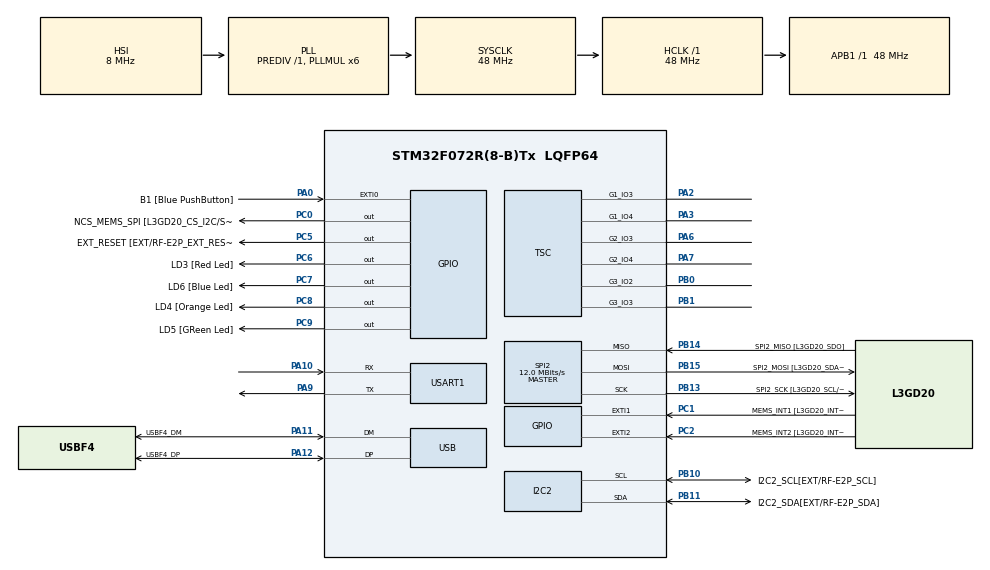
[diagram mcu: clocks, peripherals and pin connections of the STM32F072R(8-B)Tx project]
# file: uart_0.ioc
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I2C2.Timing=0x20303E5D
Mcu.Family=STM32F0
Mcu.Name=STM32F072R(8-B)Tx
Mcu.Package=LQFP64
NVIC.USART1_IRQn=true\:1\:0\:true\:false\:true\:true\:true\:true
PA0.GPIO_Label=B1 [Blue PushButton]
PA0.GPIO_ModeDefaultEXTI=GPIO_MODE_EVT_RISING
PA0.Signal=GPXTI0
PA10.Mode=Asynchronous
PA10.Signal=USART1_RX
PA11.GPIO_Label=USBF4_DM
PA11.Mode=Device
PA11.Signal=USB_DM
PA12.GPIO_Label=USBF4_DP
PA12.Mode=Device
PA12.Signal=USB_DP
PA13.GPIO_Label=SWDIO
PA13.Mode=Serial_Wire
PA13.Signal=SYS_SWDIO
PA14.GPIO_Label=SWCLK
PA14.Mode=Serial_Wire
PA14.Signal=SYS_SWCLK
PA2.Mode=G1_IO3-Channel
PA2.Signal=TSC_G1_IO3
PA3.Mode=G1_IO4-Sampling
PA3.Signal=TSC_G1_IO4
PA6.Mode=G2_IO3-Channel
PA6.Signal=TSC_G2_IO3
PA7.Mode=G2_IO4-Sampling
PA7.Signal=TSC_G2_IO4
PA9.Mode=Asynchronous
PA9.Signal=USART1_TX
PB0.Mode=G3_IO2-Channel
PB0.Signal=TSC_G3_IO2
PB1.Mode=G3_IO3-Sampling
PB1.Signal=TSC_G3_IO3
PB10.GPIO_Label=I2C2_SCL[EXT/RF-E2P_SCL]
PB10.GPIO_Pu=GPIO_PULLUP
PB10.Mode=I2C
PB10.Signal=I2C2_SCL
PB11.GPIO_Label=I2C2_SDA[EXT/RF-E2P_SDA]
PB11.GPIO_Pu=GPIO_PULLUP
PB11.Mode=I2C
PB11.Signal=I2C2_SDA
PB13.GPIO_Label=SPI2_SCK [L3GD20_SCL/SPC]
PB13.Mode=Full_Duplex_Master
PB13.Signal=SPI2_SCK
PB14.GPIO_Label=SPI2_MISO [L3GD20_SDO]
PB14.Mode=Full_Duplex_Master
PB14.Signal=SPI2_MISO
PB15.GPIO_Label=SPI2_MOSI [L3GD20_SDA/SDI]
PB15.Mode=Full_Duplex_Master
PB15.Signal=SPI2_MOSI
PC0.GPIO_Label=NCS_MEMS_SPI [L3GD20_CS_I2C/SPI]
PC0.Signal=GPIO_Output
PC1.GPIO_Label=MEMS_INT1 [L3GD20_INT1]
PC1.GPIO_ModeDefaultEXTI=GPIO_MODE_EVT_RISING
PC1.Signal=GPXTI1
PC2.GPIO_Label=MEMS_INT2 [L3GD20_INT2]
PC2.GPIO_ModeDefaultEXTI=GPIO_MODE_EVT_RISING
PC2.Signal=GPXTI2
PC5.GPIO_Label=EXT_RESET [EXT/RF-E2P_EXT_RESET]
PC5.Signal=GPIO_Output
PC6.GPIO_Label=LD3 [Red Led]
PC6.Signal=GPIO_Output
PC7.GPIO_Label=LD6 [Blue Led]
PC7.Signal=GPIO_Output
PC8.GPIO_Label=LD4 [Orange Led]
PC8.Signal=GPIO_Output
PC9.GPIO_Label=LD5 [GReen Led]
PC9.Signal=GPIO_Output
ProjectManager.HeapSize=0x200
ProjectManager.StackSize=0x400
ProjectManager.TargetToolchain=STM32CubeIDE
RCC.AHBFreq_Value=48000000
RCC.APB1Freq_Value=48000000
RCC.APB1TimFreq_Value=48000000
RCC.HCLKFreq_Value=48000000
RCC.PLLMUL=RCC_PLL_MUL6
RCC.SYSCLKFreq_VALUE=48000000
RCC.SYSCLKSource=RCC_SYSCLKSOURCE_PLLCLK
SPI2.BaudRatePrescaler=SPI_BAUDRATEPRESCALER_4
SPI2.CalculateBaudRate=12.0 MBits/s
SPI2.Direction=SPI_DIRECTION_2LINES
SPI2.Mode=SPI_MODE_MASTER
SPI2.VirtualType=VM_MASTER
USART1.VirtualMode-Asynchronous=VM_ASYNC
USB.phy_itface=PCD_PHY_EMBEDDED
USB.speed=PCD_SPEED_FULL
board=STM32F072B-DISCO

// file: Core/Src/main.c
/* USER CODE BEGIN Header */
/**
  ******************************************************************************
  * @file           : main.c
  * @brief          : Main program body
  ******************************************************************************
  * @attention
  *
  * Copyright (c) 2024 STMicroelectronics.
  * All rights reserved.
  *
  * This software is licensed under terms that can be found in the LICENSE file
  * in the root directory of this software component.
  * If no LICENSE file comes with this software, it is provided AS-IS.
  *
  ******************************************************************************
  */
/* USER CODE END Header */
#include "main.h"
#include <string.h>
/* USER CODE BEGIN Includes */
#include "stdbool.h"
/* USER CODE END Includes */
uint8_t data_rx[1];

I2C_HandleTypeDef hi2c2;

SPI_HandleTypeDef hspi2;

TSC_HandleTypeDef htsc;

UART_HandleTypeDef huart1;

PCD_HandleTypeDef hpcd_USB_FS;

void SystemClock_Config(void);
static void MX_GPIO_Init(void);
static void MX_I2C2_Init(void);
static void MX_SPI2_Init(void);
static void MX_TSC_Init(void);
static void MX_USB_PCD_Init(void);
static void MX_USART1_UART_Init(void);

/* USER CODE BEGIN 0 */

uint8_t uart1MainBuf[64];
uint8_t uart1rxLen;
bool uart1CallbackComplete = false;
void SendPongMessage(void);
/* USER CODE END 0 */

int main(void)
{

  /* MCU Configuration--------------------------------------------------------*/

  /* Reset of all peripherals, Initializes the Flash interface and the Systick. */
  HAL_Init();

  /* Configure the system clock */
  SystemClock_Config();

  /* Initialize all configured peripherals */
  MX_GPIO_Init();
  MX_I2C2_Init();
  MX_SPI2_Init();
  MX_TSC_Init();
  MX_USB_PCD_Init();
  MX_USART1_UART_Init();
  HAL_UART_Receive_IT(&huart1, data_rx, 1);

  /* Infinite loop */
  while (1)
  {
	 // HAL_GPIO_TogglePin(LD6_GPIO_Port, LD6_Pin);
	  // HAL_Delay(250);
	  if (uart1CallbackComplete){
		  uart1CallbackComplete = false;
		  if (uart1MainBuf[uart1rxLen -1] == 103){
			  SendPongMessage();
		  }
	  }
  }
}

void SystemClock_Config(void)
{
  RCC_OscInitTypeDef RCC_OscInitStruct = {0};
  RCC_ClkInitTypeDef RCC_ClkInitStruct = {0};
  RCC_PeriphCLKInitTypeDef PeriphClkInit = {0};

  /** Initializes the RCC Oscillators according to the specified parameters
  * in the RCC_OscInitTypeDef structure.
  */
  RCC_OscInitStruct.OscillatorType = RCC_OSCILLATORTYPE_HSI|RCC_OSCILLATORTYPE_HSI48;
  RCC_OscInitStruct.HSIState = RCC_HSI_ON;
  RCC_OscInitStruct.HSI48State = RCC_HSI48_ON;
  RCC_OscInitStruct.HSICalibrationValue = RCC_HSICALIBRATION_DEFAULT;
  RCC_OscInitStruct.PLL.PLLState = RCC_PLL_ON;
  RCC_OscInitStruct.PLL.PLLSource = RCC_PLLSOURCE_HSI;
  RCC_OscInitStruct.PLL.PLLMUL = RCC_PLL_MUL6;
  RCC_OscInitStruct.PLL.PREDIV = RCC_PREDIV_DIV1;
  if (HAL_RCC_OscConfig(&RCC_OscInitStruct) != HAL_OK)
  {
    Error_Handler();
  }

  /** Initializes the CPU, AHB and APB buses clocks
  */
  RCC_ClkInitStruct.ClockType = RCC_CLOCKTYPE_HCLK|RCC_CLOCKTYPE_SYSCLK
                              |RCC_CLOCKTYPE_PCLK1;
  RCC_ClkInitStruct.SYSCLKSource = RCC_SYSCLKSOURCE_PLLCLK;
  RCC_ClkInitStruct.AHBCLKDivider = RCC_SYSCLK_DIV1;
  RCC_ClkInitStruct.APB1CLKDivider = RCC_HCLK_DIV1;

  if (HAL_RCC_ClockConfig(&RCC_ClkInitStruct, FLASH_LATENCY_1) != HAL_OK)
  {
    Error_Handler();
  }
  PeriphClkInit.PeriphClockSelection = RCC_PERIPHCLK_USB|RCC_PERIPHCLK_USART1;
  PeriphClkInit.Usart1ClockSelection = RCC_USART1CLKSOURCE_PCLK1;
  PeriphClkInit.UsbClockSelection = RCC_USBCLKSOURCE_HSI48;

  if (HAL_RCCEx_PeriphCLKConfig(&PeriphClkInit) != HAL_OK)
  {
    Error_Handler();
  }
}

static void MX_I2C2_Init(void)
{

  hi2c2.Instance = I2C2;
  hi2c2.Init.Timing = 0x20303E5D;
  hi2c2.Init.OwnAddress1 = 0;
  hi2c2.Init.AddressingMode = I2C_ADDRESSINGMODE_7BIT;
  hi2c2.Init.DualAddressMode = I2C_DUALADDRESS_DISABLE;
  hi2c2.Init.OwnAddress2 = 0;
  hi2c2.Init.OwnAddress2Masks = I2C_OA2_NOMASK;
  hi2c2.Init.GeneralCallMode = I2C_GENERALCALL_DISABLE;
  hi2c2.Init.NoStretchMode = I2C_NOSTRETCH_DISABLE;
  if (HAL_I2C_Init(&hi2c2) != HAL_OK)
  {
    Error_Handler();
  }

  /** Configure Analogue filter
  */
  if (HAL_I2CEx_ConfigAnalogFilter(&hi2c2, I2C_ANALOGFILTER_ENABLE) != HAL_OK)
  {
    Error_Handler();
  }

  /** Configure Digital filter
  */
  if (HAL_I2CEx_ConfigDigitalFilter(&hi2c2, 0) != HAL_OK)
  {
    Error_Handler();
  }

}

static void MX_SPI2_Init(void)
{

  /* SPI2 parameter configuration*/
  hspi2.Instance = SPI2;
  hspi2.Init.Mode = SPI_MODE_MASTER;
  hspi2.Init.Direction = SPI_DIRECTION_2LINES;
  hspi2.Init.DataSize = SPI_DATASIZE_4BIT;
  hspi2.Init.CLKPolarity = SPI_POLARITY_LOW;
  hspi2.Init.CLKPhase = SPI_PHASE_1EDGE;
  hspi2.Init.NSS = SPI_NSS_SOFT;
  hspi2.Init.BaudRatePrescaler = SPI_BAUDRATEPRESCALER_4;
  hspi2.Init.FirstBit = SPI_FIRSTBIT_MSB;
  hspi2.Init.TIMode = SPI_TIMODE_DISABLE;
  hspi2.Init.CRCCalculation = SPI_CRCCALCULATION_DISABLE;
  hspi2.Init.CRCPolynomial = 7;
  hspi2.Init.CRCLength = SPI_CRC_LENGTH_DATASIZE;
  hspi2.Init.NSSPMode = SPI_NSS_PULSE_ENABLE;
  if (HAL_SPI_Init(&hspi2) != HAL_OK)
  {
    Error_Handler();
  }

}

static void MX_TSC_Init(void)
{

  /** Configure the TSC peripheral
  */
  htsc.Instance = TSC;
  htsc.Init.CTPulseHighLength = TSC_CTPH_2CYCLES;
  htsc.Init.CTPulseLowLength = TSC_CTPL_2CYCLES;
  htsc.Init.SpreadSpectrum = DISABLE;
  htsc.Init.SpreadSpectrumDeviation = 1;
  htsc.Init.SpreadSpectrumPrescaler = TSC_SS_PRESC_DIV1;
  htsc.Init.PulseGeneratorPrescaler = TSC_PG_PRESC_DIV4;
  htsc.Init.MaxCountValue = TSC_MCV_8191;
  htsc.Init.IODefaultMode = TSC_IODEF_OUT_PP_LOW;
  htsc.Init.SynchroPinPolarity = TSC_SYNC_POLARITY_FALLING;
  htsc.Init.AcquisitionMode = TSC_ACQ_MODE_NORMAL;
  htsc.Init.MaxCountInterrupt = DISABLE;
  htsc.Init.ChannelIOs = TSC_GROUP1_IO3|TSC_GROUP2_IO3|TSC_GROUP3_IO2;
  htsc.Init.ShieldIOs = 0;
  htsc.Init.SamplingIOs = TSC_GROUP1_IO4|TSC_GROUP2_IO4|TSC_GROUP3_IO3;
  if (HAL_TSC_Init(&htsc) != HAL_OK)
  {
    Error_Handler();
  }

}

static void MX_USART1_UART_Init(void)
{

  huart1.Instance = USART1;
  huart1.Init.BaudRate = 38400;
  huart1.Init.WordLength = UART_WORDLENGTH_8B;
  huart1.Init.StopBits = UART_STOPBITS_1;
  huart1.Init.Parity = UART_PARITY_NONE;
  huart1.Init.Mode = UART_MODE_TX_RX;
  huart1.Init.HwFlowCtl = UART_HWCONTROL_NONE;
  huart1.Init.OverSampling = UART_OVERSAMPLING_16;
  huart1.Init.OneBitSampling = UART_ONE_BIT_SAMPLE_DISABLE;
  huart1.AdvancedInit.AdvFeatureInit = UART_ADVFEATURE_NO_INIT;
  if (HAL_UART_Init(&huart1) != HAL_OK)
  {
    Error_Handler();
  }

}

static void MX_USB_PCD_Init(void)
{

  hpcd_USB_FS.Instance = USB;
  hpcd_USB_FS.Init.dev_endpoints = 8;
  hpcd_USB_FS.Init.speed = PCD_SPEED_FULL;
  hpcd_USB_FS.Init.phy_itface = PCD_PHY_EMBEDDED;
  hpcd_USB_FS.Init.low_power_enable = DISABLE;
  hpcd_USB_FS.Init.lpm_enable = DISABLE;
  hpcd_USB_FS.Init.battery_charging_enable = DISABLE;
  if (HAL_PCD_Init(&hpcd_USB_FS) != HAL_OK)
  {
    Error_Handler();
  }

}

static void MX_GPIO_Init(void)
{
  GPIO_InitTypeDef GPIO_InitStruct = {0};

  /* GPIO Ports Clock Enable */
  __HAL_RCC_GPIOC_CLK_ENABLE();
  __HAL_RCC_GPIOA_CLK_ENABLE();
  __HAL_RCC_GPIOB_CLK_ENABLE();

  /*Configure GPIO pin Output Level */
  HAL_GPIO_WritePin(GPIOC, NCS_MEMS_SPI_Pin|EXT_RESET_Pin|LD3_Pin|LD6_Pin
                          |LD4_Pin|LD5_Pin, GPIO_PIN_RESET);

  /*Configure GPIO pins : NCS_MEMS_SPI_Pin EXT_RESET_Pin LD3_Pin LD6_Pin
                           LD4_Pin LD5_Pin */
  GPIO_InitStruct.Pin = NCS_MEMS_SPI_Pin|EXT_RESET_Pin|LD3_Pin|LD6_Pin
                          |LD4_Pin|LD5_Pin;
  GPIO_InitStruct.Mode = GPIO_MODE_OUTPUT_PP;
  GPIO_InitStruct.Pull = GPIO_NOPULL;
  GPIO_InitStruct.Speed = GPIO_SPEED_FREQ_LOW;
  HAL_GPIO_Init(GPIOC, &GPIO_InitStruct);

  /*Configure GPIO pins : MEMS_INT1_Pin MEMS_INT2_Pin */
  GPIO_InitStruct.Pin = MEMS_INT1_Pin|MEMS_INT2_Pin;
  GPIO_InitStruct.Mode = GPIO_MODE_EVT_RISING;
  GPIO_InitStruct.Pull = GPIO_NOPULL;
  HAL_GPIO_Init(GPIOC, &GPIO_InitStruct);

  /*Configure GPIO pin : B1_Pin */
  GPIO_InitStruct.Pin = B1_Pin;
  GPIO_InitStruct.Mode = GPIO_MODE_EVT_RISING;
  GPIO_InitStruct.Pull = GPIO_NOPULL;
  HAL_GPIO_Init(B1_GPIO_Port, &GPIO_InitStruct);

}

/* USER CODE BEGIN 4 */
//void HAL_UART_RxHalfCpltCallback(UART_HandleTypeDef *huart)
//{
//	if (huart->Instance == USART1) {
//	        // Gelen veri işlenebilir
//        HAL_UART_Receive_IT(&huart1, data_rx, sizeof(data_rx));  // Yeniden alım başlatılır
//	    }
//}

void SendPongMessage(void)
{
    uint8_t pongMessage[5] = "pong\n"; // "pong" mesajı, satır sonu ile
    HAL_UART_Transmit(&huart1, pongMessage, 5, HAL_MAX_DELAY);
}

void HAL_UART_RxCpltCallback(UART_HandleTypeDef *huart)
{
    if (huart->Instance == USART1)  // Eğer gelen veri USART1 üzerinden geldiyse
    {
    	uart1MainBuf[uart1rxLen++] = data_rx[0] & 0xFF;
    	uart1CallbackComplete = true;
        HAL_UART_Receive_IT(&huart1, data_rx, 1); // Yeniden alım başlat
    }
}
/* USER CODE END 4 */

void Error_Handler(void)
{
  __disable_irq();
  while (1)
  {
  }
}
